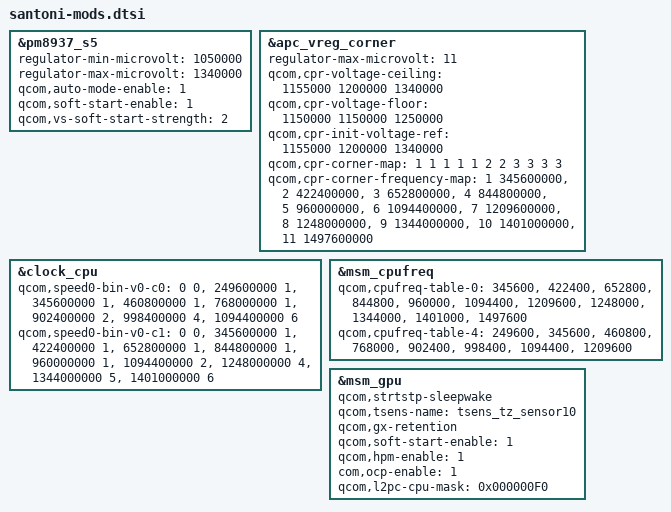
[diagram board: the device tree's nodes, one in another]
/*
 * Copyright (c) 2018, Eduardo Noyer. All rights reserved.
 *
 * This program is free software; you can redistribute it and/or modify
 * it under the terms of the GNU General Public License version 2 and
 * only version 2 as published by the Free Software Foundation.
 *
 * This program is distributed in the hope that it will be useful,
 * but WITHOUT ANY WARRANTY; without even the implied warranty of
 * MERCHANTABILITY or FITNESS FOR A PARTICULAR PURPOSE.  See the
 * GNU General Public License for more details.
 */

&pm8937_s5{
	//Set min and max Mv.
	//Original values
	//regulator-min-microvolt = <1050000>;
        //regulator-max-microvolt = <1350000>;
	//New values
	regulator-min-microvolt = <1050000>;
	regulator-max-microvolt = <1340000>;
	qcom,auto-mode-enable = <1>;
	qcom,soft-start-enable = <1>;
	qcom,vs-soft-start-strength = <2>;
};

&apc_vreg_corner {
	//Num of cpr-corner-map elements
	regulator-max-microvolt = <11>;
	//CPU Voltages
	//Original values
	//qcom,cpr-voltage-ceiling = <1155000 1225000 1350000>;
	//qcom,cpr-voltage-floor =   <1150000 1150000 1250000>;
	//qcom,cpr-init-voltage-ref = <1155000 1225000 1350000>;
	//New values
	qcom,cpr-voltage-ceiling = <1155000 1200000 1340000>;
	qcom,cpr-voltage-floor = <1150000 1150000 1250000>;
	qcom,cpr-init-voltage-ref = <1155000 1200000 1340000>;
	//CPU Frequencies Map
	qcom,cpr-corner-map = <1 1 1 1 1 2 2 3 3 3 3>;
	qcom,cpr-corner-frequency-map =
			       <1 345600000>,
			       <2 422400000>,
			       <3 652800000>,
			       <4 844800000>,
                               <5 960000000>,
                               <6 1094400000>,
                               <7 1209600000>,
                               <8 1248000000>,
                               <9 1344000000>,
                               <10 1401000000>,
                               <11 1497600000>;
};

&clock_cpu {
	qcom,speed0-bin-v0-c0 =
                       <          0 0>,
		       <  249600000 1>,
		       <  345600000 1>,
		       <  460800000 1>,
                       <  768000000 1>,
                       <  902400000 2>,
                       <  998400000 4>,
                       < 1094400000 6>;

        qcom,speed0-bin-v0-c1 =
                       <          0 0>,
		       <  345600000 1>,
    		       <  422400000 1>,
		       <  652800000 1>,
		       <  844800000 1>,
                       <  960000000 1>,
                       < 1094400000 2>,
                       < 1248000000 4>,
                       < 1344000000 5>,
                       < 1401000000 6>;
};

&msm_cpufreq {
	// CPU big frequencies map
	qcom,cpufreq-table-0 =
			<  345600 >,
  		        <  422400 >,
			<  652800 >,
			<  844800 >,
                        <  960000 >,
                        < 1094400 >,
                        < 1209600 >,
                        < 1248000 >,
                        < 1344000 >,
                        < 1401000 >,
                        < 1497600 >;

	// CPU LITTLE frequencies map
        qcom,cpufreq-table-4 =
			<  249600 >,
      		        <  345600 >,
			<  460800 >,
                        <  768000 >,
                        <  902400 >,
                        <  998400 >,
                        < 1094400 >,
                        < 1209600 >;
};
//GPU Settings
&msm_gpu{
	//Special features:
	qcom,strtstp-sleepwake; //prevent clock up when isn't needed.
	qcom,tsens-name = "tsens_tz_sensor10"; //enable sensor name for GPU temperature monitoring 
	qcom,gx-retention; //Enable regulator retention level for IDLE modes
	qcom,soft-start-enable = <1>; //enable soft start to start without current peaks that can damage device
	qcom,hpm-enable = <1>; //enable high power mode
	//qcom,boost-current-limit = <14>; //3200mA maximum
	com,ocp-enable = <1>; //enables over current protection
	qcom,l2pc-cpu-mask = <0x000000F0>; // Avoid L2PC on big cluster CPUs (CPU 4,5,6,7)
};
